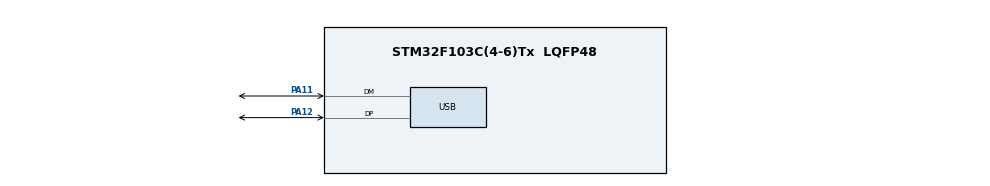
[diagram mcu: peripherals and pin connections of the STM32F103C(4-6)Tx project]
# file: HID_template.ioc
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Mcu.Family=STM32F1
Mcu.Name=STM32F103C(4-6)Tx
Mcu.Package=LQFP48
NVIC.PriorityGroup=NVIC_PRIORITYGROUP_4
NVIC.TIM1_UP_IRQn=true\:0\:0\:false\:false\:true\:true\:true
NVIC.USB_LP_CAN1_RX0_IRQn=true\:0\:0\:false\:false\:true\:false\:true
PA11.Mode=Device
PA11.Signal=USB_DM
PA12.Mode=Device
PA12.Signal=USB_DP
PA13.Mode=Serial_Wire
PA13.Signal=SYS_JTMS-SWDIO
PA14.Mode=Serial_Wire
PA14.Signal=SYS_JTCK-SWCLK
PD0-OSC_IN.Mode=HSE-External-Oscillator
PD0-OSC_IN.Signal=RCC_OSC_IN
PD1-OSC_OUT.Mode=HSE-External-Oscillator
PD1-OSC_OUT.Signal=RCC_OSC_OUT
ProjectManager.HeapSize=0x200
ProjectManager.StackSize=0x400
ProjectManager.TargetToolchain=MDK-ARM V5.32
RCC.AHBFreq_Value=72000000
RCC.APB1CLKDivider=RCC_HCLK_DIV2
RCC.APB1Freq_Value=36000000
RCC.APB1TimFreq_Value=72000000
RCC.APB2Freq_Value=72000000
RCC.APB2TimFreq_Value=72000000
RCC.HCLKFreq_Value=72000000
RCC.PLLMUL=RCC_PLL_MUL9
RCC.PLLSourceVirtual=RCC_PLLSOURCE_HSE
RCC.SYSCLKFreq_VALUE=72000000
RCC.SYSCLKSource=RCC_SYSCLKSOURCE_PLLCLK
RCC.USBFreq_Value=48000000
RCC.USBPrescaler=RCC_USBCLKSOURCE_PLL_DIV1_5
TIM1.Period=124
TIM1.Prescaler=719
USB_DEVICE.CLASS_NAME_FS=CUSTOM_HID
USB_DEVICE.CONFIGURATION_STRING_CUSTOMHID_FS=PSK INF
USB_DEVICE.CUSTOM_HID_FS_BINTERVAL=0x1
USB_DEVICE.INTERFACE_STRING_CUSTOMHID_FS=PSK HID INTERFACE
USB_DEVICE.LANGID_STRING=1033
USB_DEVICE.MANUFACTURER_STRING=NJUST 6003-Ptisak LAB INC
USB_DEVICE.PID_CUSTOMHID_FS=23333
USB_DEVICE.PRODUCT_STRING_CUSTOMHID_FS=Ptisak Pia \!(o `~')/''
USB_DEVICE.USBD_CUSTOMHID_OUTREPORT_BUF_SIZE=64
USB_DEVICE.USBD_CUSTOM_HID_REPORT_DESC_SIZE=251
USB_DEVICE.VID=6666
USB_DEVICE.VirtualMode=CustomHid
USB_DEVICE.VirtualModeFS=Custom_Hid_FS
VP_TIM1_VS_ClockSourceINT.Mode=Internal
VP_USB_DEVICE_VS_USB_DEVICE_CUSTOM_HID_FS.Mode=CUSTOM_HID_FS
board=custom

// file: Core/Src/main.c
/* USER CODE BEGIN Header */
/**
 ******************************************************************************
 * @file           : main.c
 * @brief          : Main program body
 ******************************************************************************
 * @attention
 *
 * Copyright (c) 2022 STMicroelectronics.
 * All rights reserved.
 *
 * This software is licensed under terms that can be found in the LICENSE file
 * in the root directory of this software component.
 * If no LICENSE file comes with this software, it is provided AS-IS.
 *
 ******************************************************************************
 */
/* USER CODE END Header */
#include "main.h"
#include "tim.h"
#include "usb_device.h"
#include "gpio.h"

/* USER CODE BEGIN Includes */
#include "psk_hid.h"
/* USER CODE END Includes */

void SystemClock_Config(void);

/* USER CODE BEGIN 0 */
void LL_MY_USB_Reset(void)
{
  LL_GPIO_InitTypeDef GPIO_InitStruct = {0};

  /* GPIO Ports Clock Enable */
  LL_APB2_GRP1_EnableClock(LL_APB2_GRP1_PERIPH_GPIOA);

  /**/
  LL_GPIO_ResetOutputPin(GPIOA, LL_GPIO_PIN_12);

  /**/
  GPIO_InitStruct.Pin = LL_GPIO_PIN_12;
  GPIO_InitStruct.Mode = LL_GPIO_MODE_OUTPUT;
  GPIO_InitStruct.Speed = LL_GPIO_SPEED_FREQ_LOW;
  GPIO_InitStruct.OutputType = LL_GPIO_OUTPUT_PUSHPULL;
  LL_GPIO_Init(GPIOA, &GPIO_InitStruct);

  LL_GPIO_ResetOutputPin(GPIOA, LL_GPIO_PIN_12);
  LL_mDelay(50);
  LL_GPIO_SetOutputPin(GPIOA, LL_GPIO_PIN_12);
}
void TIM1_IRQ(void)
{
  if (LL_TIM_IsActiveFlag_UPDATE(TIM1) == SET)
  {
    LL_TIM_ClearFlag_UPDATE(TIM1); // 1.25 ms
    static uint8_t i;
    switch (i)
    {
    case 0:
      send_keyboard_data();
      break;
    case 1:
      send_custom_control_data();
      break;
    case 2:
      send_touch_data();
      break;
    default:
      send_mouse_data();
    }
    i = (i + 1) % 4;
  }
}
/* USER CODE END 0 */

int main(void)
{

  /* MCU Configuration--------------------------------------------------------*/

  /* Reset of all peripherals, Initializes the Flash interface and the Systick. */
  HAL_Init();

  /* Configure the system clock */
  SystemClock_Config();

  /* USER CODE BEGIN SysInit */
  LL_MY_USB_Reset();
  /* USER CODE END SysInit */

  /* Initialize all configured peripherals */
  MX_GPIO_Init();
  MX_TIM1_Init();
  MX_USB_DEVICE_Init();
  /* USER CODE BEGIN 2 */

  mouse_init();
  keyboard_init();
  custom_init();
  touch_init();

  LL_TIM_EnableIT_UPDATE(TIM1); // ENABLE IT Update Interrupt <=> TIM_DIER_UIE = 1
  LL_TIM_EnableCounter(TIM1);   // ENABLE Counter             <=> TIM_CR1_CEN  = 1
  /* USER CODE END 2 */

  /* Infinite loop */
  /* USER CODE BEGIN WHILE */
  LL_mDelay(4000);
  mouse_move(100, 100);
	custom_press_key(VOL_DOWN, 1);
	//keyboard_press_char('x', 2);
  keyboard_press_str("hello world", 1);
	touch_set_pos(666, 666);
	touch_set_time(100);
  while (1)
  {
    /* USER CODE END WHILE */

  }
}

void SystemClock_Config(void)
{
  LL_FLASH_SetLatency(LL_FLASH_LATENCY_2);
  while (LL_FLASH_GetLatency() != LL_FLASH_LATENCY_2)
  {
  }
  LL_RCC_HSE_Enable();

  /* Wait till HSE is ready */
  while (LL_RCC_HSE_IsReady() != 1)
  {
  }
  LL_RCC_PLL_ConfigDomain_SYS(LL_RCC_PLLSOURCE_HSE_DIV_1, LL_RCC_PLL_MUL_9);
  LL_RCC_PLL_Enable();

  /* Wait till PLL is ready */
  while (LL_RCC_PLL_IsReady() != 1)
  {
  }
  LL_RCC_SetAHBPrescaler(LL_RCC_SYSCLK_DIV_1);
  LL_RCC_SetAPB1Prescaler(LL_RCC_APB1_DIV_2);
  LL_RCC_SetAPB2Prescaler(LL_RCC_APB2_DIV_1);
  LL_RCC_SetSysClkSource(LL_RCC_SYS_CLKSOURCE_PLL);

  /* Wait till System clock is ready */
  while (LL_RCC_GetSysClkSource() != LL_RCC_SYS_CLKSOURCE_STATUS_PLL)
  {
  }
  LL_SetSystemCoreClock(72000000);

  /* Update the time base */
  if (HAL_InitTick(TICK_INT_PRIORITY) != HAL_OK)
  {
    Error_Handler();
  }
  LL_RCC_SetUSBClockSource(LL_RCC_USB_CLKSOURCE_PLL_DIV_1_5);
}

void Error_Handler(void)
{
  __disable_irq();
  while (1)
  {
  }
}
